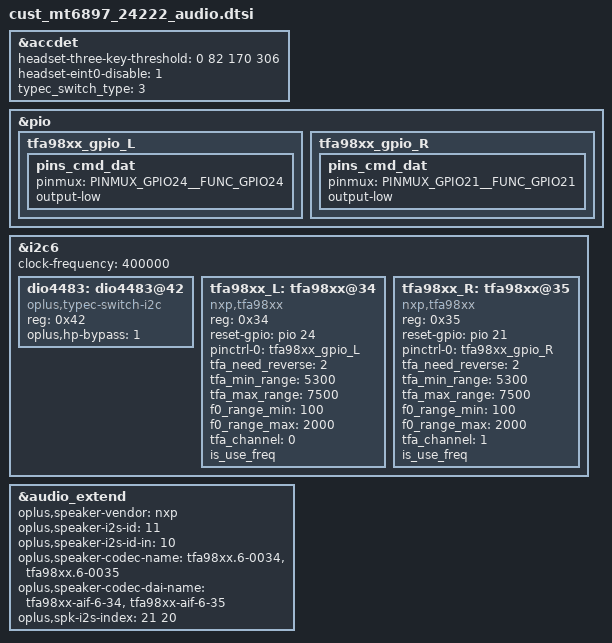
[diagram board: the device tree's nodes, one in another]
// SPDX-License-Identifier: GPL-2.0
/* Copyright (c) 2020 MediaTek Inc. */

&accdet {
	headset-three-key-threshold = <0 82 170 306>;
	headset-eint0-disable = <1>;
	typec_switch_type = <3>;
};

&pio {
	tfa98xx_gpio_L: tfa98xx_gpio_L {
		pins_cmd_dat {
			pinmux = <PINMUX_GPIO24__FUNC_GPIO24>;
			output-low;
		};
	};

	tfa98xx_gpio_R: tfa98xx_gpio_R {
		pins_cmd_dat {
			pinmux = <PINMUX_GPIO21__FUNC_GPIO21>;
			output-low;
		};
	};
};

&i2c6 {
	clock-frequency = <400000>;

	dio4483: dio4483@42 {
		compatible = "oplus,typec-switch-i2c";
		reg = <0x42>;
		// add for supporting type-c headphone detect bypass
		oplus,hp-bypass = <1>;
		status = "okay";
	};

	tfa98xx_L: tfa98xx@34 {
		compatible = "nxp,tfa98xx";
		reg = <0x34>;
		reset-gpio = <&pio 24 0>;
		pinctrl-names = "default";
		pinctrl-0 = <&tfa98xx_gpio_L>;
		/*2024/08/16, used to distinguish different project pcb version*/
		tfa_need_reverse = <2>;
		tfa_min_range = <5300>;
		tfa_max_range = <7500>;
		f0_range_min = <100>;
		f0_range_max = <2000>;
		tfa_channel = <0>;
		is_use_freq;
		status = "okay";
	};

	tfa98xx_R: tfa98xx@35 {
		compatible = "nxp,tfa98xx";
		reg = <0x35>;
		reset-gpio = <&pio 21 0>;
		pinctrl-names = "default";
		pinctrl-0 = <&tfa98xx_gpio_R>;
		/*2024/08/16, used to distinguish different project pcb version*/
		tfa_need_reverse = <2>;
		tfa_min_range = <5300>;
		tfa_max_range = <7500>;
		f0_range_min = <100>;
		f0_range_max = <2000>;
		tfa_channel = <1>;
		is_use_freq;
		status = "okay";
	};
};

&audio_extend {
	//for nxp speaker
	oplus,speaker-vendor = "nxp";
	oplus,speaker-i2s-id = <11>;
	oplus,speaker-i2s-id-in = <10>;
	oplus,speaker-codec-name = "tfa98xx.6-0034","tfa98xx.6-0035";
	oplus,speaker-codec-dai-name = "tfa98xx-aif-6-34","tfa98xx-aif-6-35";
	oplus,spk-i2s-index = <21 20>;
};


